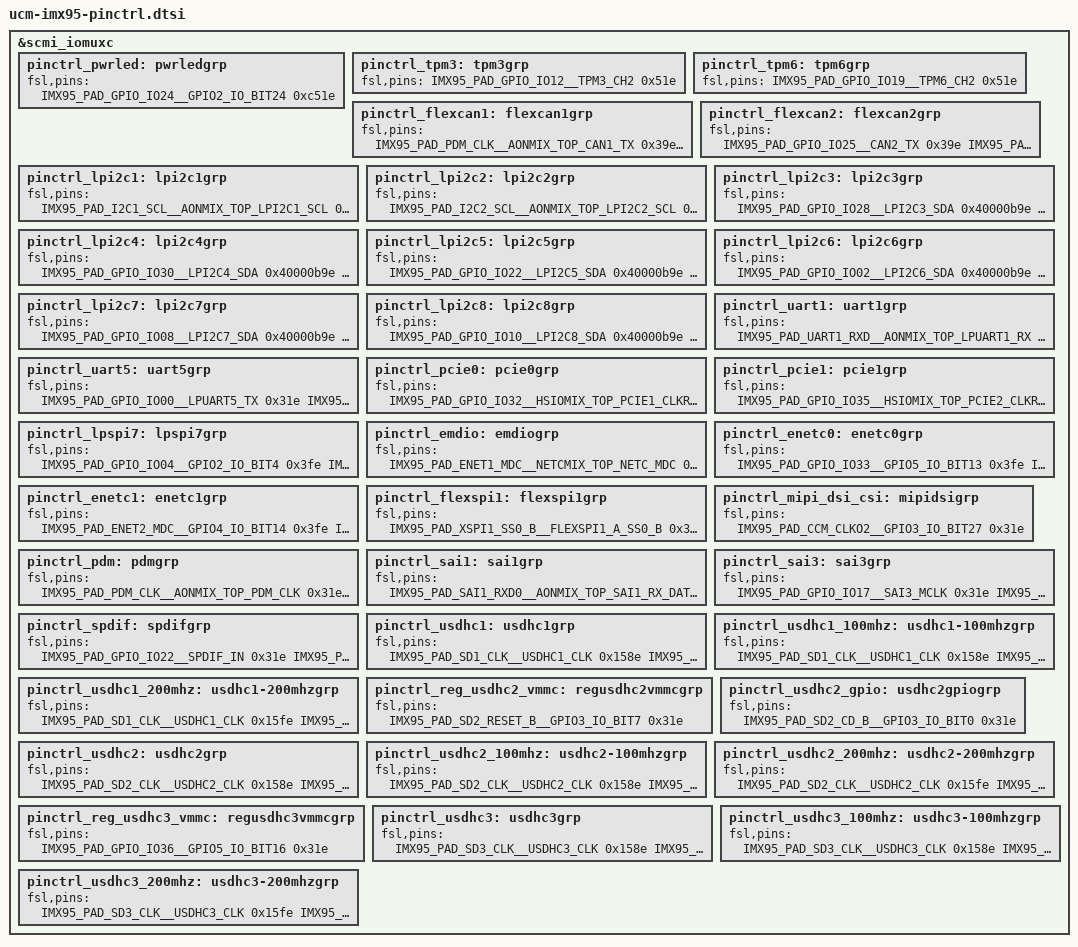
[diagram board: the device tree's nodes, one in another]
#include "../freescale/imx95.dtsi"

&scmi_iomuxc {
	pinctrl_pwrled: pwrledgrp {
		fsl,pins = <
			IMX95_PAD_GPIO_IO24__GPIO2_IO_BIT24		0xc51e
		>;
	};

	pinctrl_tpm3: tpm3grp {
		fsl,pins = <
			IMX95_PAD_GPIO_IO12__TPM3_CH2			0x51e
		>;
	};

	pinctrl_tpm6: tpm6grp {
		fsl,pins = <
			IMX95_PAD_GPIO_IO19__TPM6_CH2			0x51e
		>;
	};

	pinctrl_flexcan1: flexcan1grp {
		fsl,pins = <
			IMX95_PAD_PDM_CLK__AONMIX_TOP_CAN1_TX		0x39e
			IMX95_PAD_PDM_BIT_STREAM0__AONMIX_TOP_CAN1_RX	0x39e
		>;
	};

	pinctrl_flexcan2: flexcan2grp {
		fsl,pins = <
			IMX95_PAD_GPIO_IO25__CAN2_TX			0x39e
			IMX95_PAD_GPIO_IO27__CAN2_RX			0x39e
		>;
	};

	pinctrl_lpi2c1: lpi2c1grp {
		fsl,pins = <
			IMX95_PAD_I2C1_SCL__AONMIX_TOP_LPI2C1_SCL	0x40000b9e
			IMX95_PAD_I2C1_SDA__AONMIX_TOP_LPI2C1_SDA	0x40000b9e
		>;
	};

	pinctrl_lpi2c2: lpi2c2grp {
		fsl,pins = <
			IMX95_PAD_I2C2_SCL__AONMIX_TOP_LPI2C2_SCL	0x40000b9e
			IMX95_PAD_I2C2_SDA__AONMIX_TOP_LPI2C2_SDA	0x40000b9e
		>;
	};

	pinctrl_lpi2c3: lpi2c3grp {
		fsl,pins = <
			IMX95_PAD_GPIO_IO28__LPI2C3_SDA			0x40000b9e
			IMX95_PAD_GPIO_IO29__LPI2C3_SCL			0x40000b9e
		>;
	};

	pinctrl_lpi2c4: lpi2c4grp {
		fsl,pins = <
			IMX95_PAD_GPIO_IO30__LPI2C4_SDA			0x40000b9e
			IMX95_PAD_GPIO_IO31__LPI2C4_SCL			0x40000b9e
		>;
	};

	pinctrl_lpi2c5: lpi2c5grp {
		fsl,pins = <
			IMX95_PAD_GPIO_IO22__LPI2C5_SDA			0x40000b9e
			IMX95_PAD_GPIO_IO23__LPI2C5_SCL			0x40000b9e
		>;
	};

	pinctrl_lpi2c6: lpi2c6grp {
		fsl,pins = <
			IMX95_PAD_GPIO_IO02__LPI2C6_SDA			0x40000b9e
			IMX95_PAD_GPIO_IO03__LPI2C6_SCL			0x40000b9e
		>;
	};

	pinctrl_lpi2c7: lpi2c7grp {
		fsl,pins = <
			IMX95_PAD_GPIO_IO08__LPI2C7_SDA			0x40000b9e
			IMX95_PAD_GPIO_IO09__LPI2C7_SCL			0x40000b9e
		>;
	};

	pinctrl_lpi2c8: lpi2c8grp {
		fsl,pins = <
			IMX95_PAD_GPIO_IO10__LPI2C8_SDA			0x40000b9e
			IMX95_PAD_GPIO_IO11__LPI2C8_SCL			0x40000b9e
		>;
	};

	pinctrl_uart1: uart1grp {
		fsl,pins = <
			IMX95_PAD_UART1_RXD__AONMIX_TOP_LPUART1_RX      0x31e
			IMX95_PAD_UART1_TXD__AONMIX_TOP_LPUART1_TX      0x31e
		>;
	};

	pinctrl_uart5: uart5grp {
		fsl,pins = <
			IMX95_PAD_GPIO_IO00__LPUART5_TX			0x31e
			IMX95_PAD_GPIO_IO01__LPUART5_RX			0x31e
			IMX95_PAD_GPIO_IO02__LPUART5_CTS_B		0x31e
			IMX95_PAD_GPIO_IO03__LPUART5_RTS_B		0x31e
		>;
	};

	pinctrl_pcie0: pcie0grp {
		fsl,pins = <
			IMX95_PAD_GPIO_IO32__HSIOMIX_TOP_PCIE1_CLKREQ_B		0x4000031e
			IMX95_PAD_GPIO_IO35__GPIO5_IO_BIT15                     0x3fe
		>;
	};

	pinctrl_pcie1: pcie1grp {
		fsl,pins = <
			IMX95_PAD_GPIO_IO35__HSIOMIX_TOP_PCIE2_CLKREQ_B		0x4000031e
			IMX95_PAD_GPIO_IO18__GPIO2_IO_BIT18                    0x3fe
		>;
	};

	pinctrl_lpspi7: lpspi7grp {
		fsl,pins = <
			IMX95_PAD_GPIO_IO04__GPIO2_IO_BIT4	0x3fe
			IMX95_PAD_GPIO_IO05__LPSPI7_SIN		0x3fe
			IMX95_PAD_GPIO_IO06__LPSPI7_SOUT	0x3fe
			IMX95_PAD_GPIO_IO07__LPSPI7_SCK		0x3fe
		>;
	};

	pinctrl_emdio: emdiogrp{
		fsl,pins = <
			IMX95_PAD_ENET1_MDC__NETCMIX_TOP_NETC_MDC		0x57e
			IMX95_PAD_ENET1_MDIO__NETCMIX_TOP_NETC_MDIO		0x97e
		>;
	};

	pinctrl_enetc0: enetc0grp {
		fsl,pins = <
			IMX95_PAD_GPIO_IO33__GPIO5_IO_BIT13			0x3fe
			IMX95_PAD_ENET1_TD3__NETCMIX_TOP_ETH0_RGMII_TD3		0x57e
			IMX95_PAD_ENET1_TD2__NETCMIX_TOP_ETH0_RGMII_TD2		0x57e
			IMX95_PAD_ENET1_TD1__NETCMIX_TOP_ETH0_RGMII_TD1		0x57e
			IMX95_PAD_ENET1_TD0__NETCMIX_TOP_ETH0_RGMII_TD0		0x57e
			IMX95_PAD_ENET1_TX_CTL__NETCMIX_TOP_ETH0_RGMII_TX_CTL	0x57e
			IMX95_PAD_ENET1_TXC__NETCMIX_TOP_ETH0_RGMII_TX_CLK	0x58e
			IMX95_PAD_ENET1_RX_CTL__NETCMIX_TOP_ETH0_RGMII_RX_CTL	0x57e
			IMX95_PAD_ENET1_RXC__NETCMIX_TOP_ETH0_RGMII_RX_CLK	0x58e
			IMX95_PAD_ENET1_RD0__NETCMIX_TOP_ETH0_RGMII_RD0		0x57e
			IMX95_PAD_ENET1_RD1__NETCMIX_TOP_ETH0_RGMII_RD1		0x57e
			IMX95_PAD_ENET1_RD2__NETCMIX_TOP_ETH0_RGMII_RD2		0x57e
			IMX95_PAD_ENET1_RD3__NETCMIX_TOP_ETH0_RGMII_RD3		0x57e
		>;
	};

	pinctrl_enetc1: enetc1grp {
		fsl,pins = <
			IMX95_PAD_ENET2_MDC__GPIO4_IO_BIT14			0x3fe
			IMX95_PAD_ENET2_TD3__NETCMIX_TOP_ETH1_RGMII_TD3		0x57e
			IMX95_PAD_ENET2_TD2__NETCMIX_TOP_ETH1_RGMII_TD2		0x57e
			IMX95_PAD_ENET2_TD1__NETCMIX_TOP_ETH1_RGMII_TD1		0x57e
			IMX95_PAD_ENET2_TD0__NETCMIX_TOP_ETH1_RGMII_TD0		0x57e
			IMX95_PAD_ENET2_TX_CTL__NETCMIX_TOP_ETH1_RGMII_TX_CTL	0x57e
			IMX95_PAD_ENET2_TXC__NETCMIX_TOP_ETH1_RGMII_TX_CLK	0x58e
			IMX95_PAD_ENET2_RX_CTL__NETCMIX_TOP_ETH1_RGMII_RX_CTL	0x57e
			IMX95_PAD_ENET2_RXC__NETCMIX_TOP_ETH1_RGMII_RX_CLK	0x58e
			IMX95_PAD_ENET2_RD0__NETCMIX_TOP_ETH1_RGMII_RD0		0x57e
			IMX95_PAD_ENET2_RD1__NETCMIX_TOP_ETH1_RGMII_RD1		0x57e
			IMX95_PAD_ENET2_RD2__NETCMIX_TOP_ETH1_RGMII_RD2		0x57e
			IMX95_PAD_ENET2_RD3__NETCMIX_TOP_ETH1_RGMII_RD3		0x57e
		>;
	};

	pinctrl_flexspi1: flexspi1grp {
		fsl,pins = <
			IMX95_PAD_XSPI1_SS0_B__FLEXSPI1_A_SS0_B			0x3fe
			IMX95_PAD_XSPI1_SS1_B__GPIO5_IO_BIT11			0x3fe
			IMX95_PAD_XSPI1_SCLK__FLEXSPI1_A_SCLK			0x3fe
			IMX95_PAD_XSPI1_DQS__FLEXSPI1_A_DQS			0x3fe
			IMX95_PAD_XSPI1_DATA0__FLEXSPI1_A_DATA_BIT0		0x3fe
			IMX95_PAD_XSPI1_DATA1__FLEXSPI1_A_DATA_BIT1		0x3fe
			IMX95_PAD_XSPI1_DATA2__FLEXSPI1_A_DATA_BIT2		0x3fe
			IMX95_PAD_XSPI1_DATA3__FLEXSPI1_A_DATA_BIT3		0x3fe
			IMX95_PAD_XSPI1_DATA4__FLEXSPI1_A_DATA_BIT4		0x3fe
			IMX95_PAD_XSPI1_DATA5__FLEXSPI1_A_DATA_BIT5		0x3fe
			IMX95_PAD_XSPI1_DATA6__FLEXSPI1_A_DATA_BIT6		0x3fe
			IMX95_PAD_XSPI1_DATA7__FLEXSPI1_A_DATA_BIT7		0x3fe
		>;
	};

	pinctrl_mipi_dsi_csi: mipidsigrp {
		fsl,pins = <
			IMX95_PAD_CCM_CLKO2__GPIO3_IO_BIT27			0x31e
		>;
	};

	pinctrl_pdm: pdmgrp {
		fsl,pins = <
			IMX95_PAD_PDM_CLK__AONMIX_TOP_PDM_CLK				0x31e
			IMX95_PAD_PDM_BIT_STREAM0__AONMIX_TOP_PDM_BIT_STREAM_BIT0	0x31e
		>;
	};

	pinctrl_sai1: sai1grp {
		fsl,pins = <
			IMX95_PAD_SAI1_RXD0__AONMIX_TOP_SAI1_RX_DATA_BIT0    0x31e
			IMX95_PAD_SAI1_TXC__AONMIX_TOP_SAI1_TX_BCLK      0x31e
			IMX95_PAD_SAI1_TXFS__AONMIX_TOP_SAI1_TX_SYNC     0x31e
			IMX95_PAD_SAI1_TXD0__AONMIX_TOP_SAI1_TX_DATA_BIT0    0x31e
		>;
	};

	pinctrl_sai3: sai3grp {
		fsl,pins = <
			IMX95_PAD_GPIO_IO17__SAI3_MCLK				0x31e
			IMX95_PAD_GPIO_IO16__SAI3_TX_BCLK			0x31e
			IMX95_PAD_GPIO_IO26__SAI3_TX_SYNC			0x31e
			IMX95_PAD_GPIO_IO20__SAI3_RX_DATA_BIT0			0x31e
			IMX95_PAD_GPIO_IO21__SAI3_TX_DATA_BIT0			0x31e
		>;
	};

	pinctrl_spdif: spdifgrp {
		fsl,pins = <
			IMX95_PAD_GPIO_IO22__SPDIF_IN				0x31e
			IMX95_PAD_GPIO_IO23__SPDIF_OUT				0x31e
		>;
	};

	pinctrl_usdhc1: usdhc1grp {
		fsl,pins = <
			IMX95_PAD_SD1_CLK__USDHC1_CLK				0x158e
			IMX95_PAD_SD1_CMD__USDHC1_CMD				0x138e
			IMX95_PAD_SD1_DATA0__USDHC1_DATA0			0x138e
			IMX95_PAD_SD1_DATA1__USDHC1_DATA1			0x138e
			IMX95_PAD_SD1_DATA2__USDHC1_DATA2			0x138e
			IMX95_PAD_SD1_DATA3__USDHC1_DATA3			0x138e
			IMX95_PAD_SD1_DATA4__USDHC1_DATA4			0x138e
			IMX95_PAD_SD1_DATA5__USDHC1_DATA5			0x138e
			IMX95_PAD_SD1_DATA6__USDHC1_DATA6			0x138e
			IMX95_PAD_SD1_DATA7__USDHC1_DATA7			0x138e
			IMX95_PAD_SD1_STROBE__USDHC1_STROBE			0x158e
		>;
	};

	pinctrl_usdhc1_100mhz: usdhc1-100mhzgrp {
		fsl,pins = <
			IMX95_PAD_SD1_CLK__USDHC1_CLK				0x158e
			IMX95_PAD_SD1_CMD__USDHC1_CMD				0x138e
			IMX95_PAD_SD1_DATA0__USDHC1_DATA0			0x138e
			IMX95_PAD_SD1_DATA1__USDHC1_DATA1			0x138e
			IMX95_PAD_SD1_DATA2__USDHC1_DATA2			0x138e
			IMX95_PAD_SD1_DATA3__USDHC1_DATA3			0x138e
			IMX95_PAD_SD1_DATA4__USDHC1_DATA4			0x138e
			IMX95_PAD_SD1_DATA5__USDHC1_DATA5			0x138e
			IMX95_PAD_SD1_DATA6__USDHC1_DATA6			0x138e
			IMX95_PAD_SD1_DATA7__USDHC1_DATA7			0x138e
			IMX95_PAD_SD1_STROBE__USDHC1_STROBE			0x158e
		>;
	};

	pinctrl_usdhc1_200mhz: usdhc1-200mhzgrp {
		fsl,pins = <
			IMX95_PAD_SD1_CLK__USDHC1_CLK				0x15fe
			IMX95_PAD_SD1_CMD__USDHC1_CMD				0x13fe
			IMX95_PAD_SD1_DATA0__USDHC1_DATA0			0x13fe
			IMX95_PAD_SD1_DATA1__USDHC1_DATA1			0x13fe
			IMX95_PAD_SD1_DATA2__USDHC1_DATA2			0x13fe
			IMX95_PAD_SD1_DATA3__USDHC1_DATA3			0x13fe
			IMX95_PAD_SD1_DATA4__USDHC1_DATA4			0x13fe
			IMX95_PAD_SD1_DATA5__USDHC1_DATA5			0x13fe
			IMX95_PAD_SD1_DATA6__USDHC1_DATA6			0x13fe
			IMX95_PAD_SD1_DATA7__USDHC1_DATA7			0x13fe
			IMX95_PAD_SD1_STROBE__USDHC1_STROBE			0x15fe
		>;
	};

	pinctrl_reg_usdhc2_vmmc: regusdhc2vmmcgrp {
		fsl,pins = <
			IMX95_PAD_SD2_RESET_B__GPIO3_IO_BIT7			0x31e
		>;
	};

	pinctrl_usdhc2_gpio: usdhc2gpiogrp {
		fsl,pins = <
			IMX95_PAD_SD2_CD_B__GPIO3_IO_BIT0			0x31e
		>;
	};

	pinctrl_usdhc2: usdhc2grp {
		fsl,pins = <
			IMX95_PAD_SD2_CLK__USDHC2_CLK				0x158e
			IMX95_PAD_SD2_CMD__USDHC2_CMD				0x138e
			IMX95_PAD_SD2_DATA0__USDHC2_DATA0			0x138e
			IMX95_PAD_SD2_DATA1__USDHC2_DATA1			0x138e
			IMX95_PAD_SD2_DATA2__USDHC2_DATA2			0x138e
			IMX95_PAD_SD2_DATA3__USDHC2_DATA3			0x138e
			IMX95_PAD_SD2_VSELECT__USDHC2_VSELECT			0x51e
		>;
	};

	pinctrl_usdhc2_100mhz: usdhc2-100mhzgrp {
		fsl,pins = <
			IMX95_PAD_SD2_CLK__USDHC2_CLK				0x158e
			IMX95_PAD_SD2_CMD__USDHC2_CMD				0x138e
			IMX95_PAD_SD2_DATA0__USDHC2_DATA0			0x138e
			IMX95_PAD_SD2_DATA1__USDHC2_DATA1			0x138e
			IMX95_PAD_SD2_DATA2__USDHC2_DATA2			0x138e
			IMX95_PAD_SD2_DATA3__USDHC2_DATA3			0x138e
			IMX95_PAD_SD2_VSELECT__USDHC2_VSELECT			0x51e
		>;
	};

	pinctrl_usdhc2_200mhz: usdhc2-200mhzgrp {
		fsl,pins = <
			IMX95_PAD_SD2_CLK__USDHC2_CLK				0x15fe
			IMX95_PAD_SD2_CMD__USDHC2_CMD				0x13fe
			IMX95_PAD_SD2_DATA0__USDHC2_DATA0			0x13fe
			IMX95_PAD_SD2_DATA1__USDHC2_DATA1			0x13fe
			IMX95_PAD_SD2_DATA2__USDHC2_DATA2			0x13fe
			IMX95_PAD_SD2_DATA3__USDHC2_DATA3			0x13fe
			IMX95_PAD_SD2_VSELECT__USDHC2_VSELECT			0x51e
		>;
	};

	pinctrl_reg_usdhc3_vmmc: regusdhc3vmmcgrp {
		fsl,pins = <
			IMX95_PAD_GPIO_IO36__GPIO5_IO_BIT16                    0x31e
		>;
	};

	pinctrl_usdhc3: usdhc3grp {
		fsl,pins = <
			IMX95_PAD_SD3_CLK__USDHC3_CLK				0x158e
			IMX95_PAD_SD3_CMD__USDHC3_CMD				0x138e
			IMX95_PAD_SD3_DATA0__USDHC3_DATA0			0x138e
			IMX95_PAD_SD3_DATA1__USDHC3_DATA1			0x138e
			IMX95_PAD_SD3_DATA2__USDHC3_DATA2			0x138e
			IMX95_PAD_SD3_DATA3__USDHC3_DATA3			0x138e
		>;
	};

	pinctrl_usdhc3_100mhz: usdhc3-100mhzgrp {
		fsl,pins = <
			IMX95_PAD_SD3_CLK__USDHC3_CLK				0x158e
			IMX95_PAD_SD3_CMD__USDHC3_CMD				0x138e
			IMX95_PAD_SD3_DATA0__USDHC3_DATA0			0x138e
			IMX95_PAD_SD3_DATA1__USDHC3_DATA1			0x138e
			IMX95_PAD_SD3_DATA2__USDHC3_DATA2			0x138e
			IMX95_PAD_SD3_DATA3__USDHC3_DATA3			0x138e
		>;
	};

	pinctrl_usdhc3_200mhz: usdhc3-200mhzgrp {
		fsl,pins = <
			IMX95_PAD_SD3_CLK__USDHC3_CLK				0x15fe
			IMX95_PAD_SD3_CMD__USDHC3_CMD				0x13fe
			IMX95_PAD_SD3_DATA0__USDHC3_DATA0			0x13fe
			IMX95_PAD_SD3_DATA1__USDHC3_DATA1			0x13fe
			IMX95_PAD_SD3_DATA2__USDHC3_DATA2			0x13fe
			IMX95_PAD_SD3_DATA3__USDHC3_DATA3			0x13fe
		>;
	};
};
